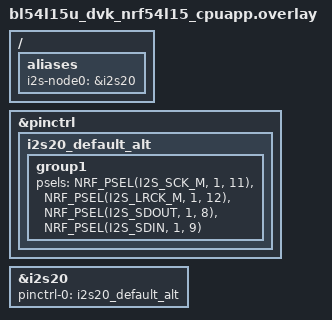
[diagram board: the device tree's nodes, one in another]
/*
 * Copyright (c) 2024 Nordic Semiconductor ASA
 * Copyright (c) 2025 Ezurio LLC
 *
 * SPDX-License-Identifier: Apache-2.0
 */

/* i2s-node0 is the transmitter/receiver */

/ {
	aliases {
		i2s-node0 = &i2s20;
	};
};

&pinctrl {
	i2s20_default_alt: i2s20_default_alt {
		group1 {
			psels = <NRF_PSEL(I2S_SCK_M, 1, 11)>,
				<NRF_PSEL(I2S_LRCK_M, 1, 12)>,
				<NRF_PSEL(I2S_SDOUT, 1, 8)>,
				<NRF_PSEL(I2S_SDIN, 1, 9)>;
		};
	};
};

&i2s20 {
	status = "okay";
	pinctrl-0 = <&i2s20_default_alt>;
	pinctrl-names = "default";
};
